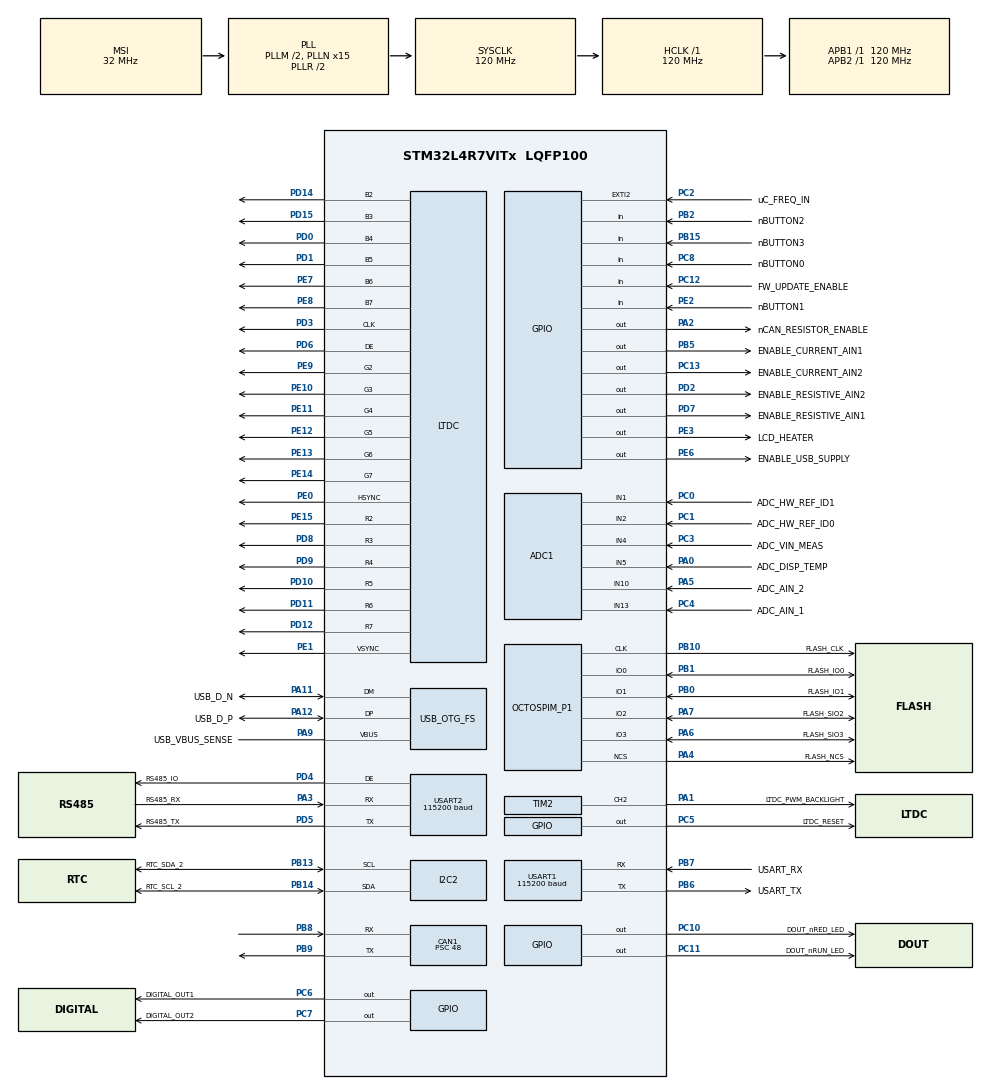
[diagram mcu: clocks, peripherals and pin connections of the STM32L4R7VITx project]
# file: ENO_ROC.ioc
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ADC1.Channel-0\#ChannelRegularConversion=ADC_CHANNEL_2
ADC1.Channel-1\#ChannelRegularConversion=ADC_CHANNEL_1
ADC1.Channel-2\#ChannelRegularConversion=ADC_CHANNEL_4
ADC1.Channel-3\#ChannelRegularConversion=ADC_CHANNEL_5
ADC1.Channel-4\#ChannelRegularConversion=ADC_CHANNEL_13
ADC1.Channel-5\#ChannelRegularConversion=ADC_CHANNEL_10
ADC1.Channel-6\#ChannelRegularConversion=ADC_CHANNEL_TEMPSENSOR
ADC1.Channel-7\#ChannelRegularConversion=ADC_CHANNEL_VREFINT
ADC1.ClockPrescaler=ADC_CLOCK_ASYNC_DIV12
ADC1.ContinuousConvMode=ENABLE
ADC1.DMAContinuousRequests=ENABLE
ADC1.EOCSelection=ADC_EOC_SEQ_CONV
ADC1.ExternalTrigConv=ADC_SOFTWARE_START
ADC1.NbrOfConversion=8
ADC1.NbrOfConversionFlag=1
ADC1.OffsetNumber-0\#ChannelRegularConversion=ADC_OFFSET_NONE
ADC1.OffsetNumber-1\#ChannelRegularConversion=ADC_OFFSET_NONE
ADC1.OffsetNumber-2\#ChannelRegularConversion=ADC_OFFSET_NONE
ADC1.OffsetNumber-3\#ChannelRegularConversion=ADC_OFFSET_NONE
ADC1.OffsetNumber-4\#ChannelRegularConversion=ADC_OFFSET_NONE
ADC1.OffsetNumber-5\#ChannelRegularConversion=ADC_OFFSET_NONE
ADC1.OffsetNumber-6\#ChannelRegularConversion=ADC_OFFSET_NONE
ADC1.OffsetNumber-7\#ChannelRegularConversion=ADC_OFFSET_NONE
ADC1.Overrun=ADC_OVR_DATA_OVERWRITTEN
ADC1.Rank-0\#ChannelRegularConversion=1
ADC1.Rank-1\#ChannelRegularConversion=2
ADC1.Rank-2\#ChannelRegularConversion=3
ADC1.Rank-3\#ChannelRegularConversion=4
ADC1.Rank-4\#ChannelRegularConversion=5
ADC1.Rank-5\#ChannelRegularConversion=6
ADC1.Rank-6\#ChannelRegularConversion=7
ADC1.Rank-7\#ChannelRegularConversion=8
ADC1.SamplingTime-0\#ChannelRegularConversion=ADC_SAMPLETIME_247CYCLES_5
ADC1.SamplingTime-1\#ChannelRegularConversion=ADC_SAMPLETIME_247CYCLES_5
ADC1.SamplingTime-2\#ChannelRegularConversion=ADC_SAMPLETIME_247CYCLES_5
ADC1.SamplingTime-3\#ChannelRegularConversion=ADC_SAMPLETIME_247CYCLES_5
ADC1.SamplingTime-4\#ChannelRegularConversion=ADC_SAMPLETIME_247CYCLES_5
ADC1.SamplingTime-5\#ChannelRegularConversion=ADC_SAMPLETIME_247CYCLES_5
ADC1.SamplingTime-6\#ChannelRegularConversion=ADC_SAMPLETIME_247CYCLES_5
ADC1.SamplingTime-7\#ChannelRegularConversion=ADC_SAMPLETIME_640CYCLES_5
ADC1.master=1
CAN1.BS1=CAN_BS1_4TQ
CAN1.BS2=CAN_BS2_5TQ
CAN1.CalculateBaudRate=250000
CAN1.CalculateTimeBit=4000
CAN1.CalculateTimeQuantum=400.0
CAN1.Mode=CAN_MODE_NORMAL
CAN1.NART=ENABLE
CAN1.Prescaler=48
CAN1.SJW=CAN_SJW_1TQ
DMA2D.ColorMode=DMA2D_OUTPUT_RGB888
DMA2D.InputAlphaForeground=255
DMA2D.InputColorModeForeground=DMA2D_INPUT_RGB888
DMA2D.Mode=DMA2D_M2M
Dma.ADC1.0.Direction=DMA_PERIPH_TO_MEMORY
Dma.ADC1.0.EventEnable=DISABLE
Dma.ADC1.0.Instance=DMA1_Channel1
Dma.ADC1.0.MemDataAlignment=DMA_MDATAALIGN_HALFWORD
Dma.ADC1.0.MemInc=DMA_MINC_ENABLE
Dma.ADC1.0.Mode=DMA_CIRCULAR
Dma.ADC1.0.PeriphDataAlignment=DMA_PDATAALIGN_HALFWORD
Dma.ADC1.0.PeriphInc=DMA_PINC_DISABLE
Dma.ADC1.0.Polarity=HAL_DMAMUX_REQUEST_GEN_RISING
Dma.ADC1.0.Priority=DMA_PRIORITY_LOW
Dma.ADC1.0.RequestNumber=1
Dma.ADC1.0.SignalID=NONE
Dma.ADC1.0.SyncEnable=DISABLE
Dma.ADC1.0.SyncPolarity=HAL_DMAMUX_SYNC_NO_EVENT
Dma.ADC1.0.SyncRequestNumber=1
Dma.ADC1.0.SyncSignalID=NONE
Dma.Request0=ADC1
Dma.Request1=USART1_RX
Dma.Request2=USART2_RX
Dma.USART1_RX.1.Direction=DMA_PERIPH_TO_MEMORY
Dma.USART1_RX.1.EventEnable=DISABLE
Dma.USART1_RX.1.Instance=DMA1_Channel2
Dma.USART1_RX.1.MemDataAlignment=DMA_MDATAALIGN_BYTE
Dma.USART1_RX.1.MemInc=DMA_MINC_ENABLE
Dma.USART1_RX.1.Mode=DMA_CIRCULAR
Dma.USART1_RX.1.PeriphDataAlignment=DMA_PDATAALIGN_BYTE
Dma.USART1_RX.1.PeriphInc=DMA_PINC_DISABLE
Dma.USART1_RX.1.Polarity=HAL_DMAMUX_REQUEST_GEN_RISING
Dma.USART1_RX.1.Priority=DMA_PRIORITY_LOW
Dma.USART1_RX.1.RequestNumber=1
Dma.USART1_RX.1.SignalID=NONE
Dma.USART1_RX.1.SyncEnable=DISABLE
Dma.USART1_RX.1.SyncPolarity=HAL_DMAMUX_SYNC_NO_EVENT
Dma.USART1_RX.1.SyncRequestNumber=1
Dma.USART1_RX.1.SyncSignalID=NONE
Dma.USART2_RX.2.Direction=DMA_PERIPH_TO_MEMORY
Dma.USART2_RX.2.EventEnable=DISABLE
Dma.USART2_RX.2.Instance=DMA1_Channel3
Dma.USART2_RX.2.MemDataAlignment=DMA_MDATAALIGN_BYTE
Dma.USART2_RX.2.MemInc=DMA_MINC_ENABLE
Dma.USART2_RX.2.Mode=DMA_CIRCULAR
Dma.USART2_RX.2.PeriphDataAlignment=DMA_PDATAALIGN_BYTE
Dma.USART2_RX.2.PeriphInc=DMA_PINC_DISABLE
Dma.USART2_RX.2.Polarity=HAL_DMAMUX_REQUEST_GEN_RISING
Dma.USART2_RX.2.Priority=DMA_PRIORITY_LOW
Dma.USART2_RX.2.RequestNumber=1
Dma.USART2_RX.2.SignalID=NONE
Dma.USART2_RX.2.SyncEnable=DISABLE
Dma.USART2_RX.2.SyncPolarity=HAL_DMAMUX_SYNC_NO_EVENT
Dma.USART2_RX.2.SyncRequestNumber=1
Dma.USART2_RX.2.SyncSignalID=NONE
FATFS._FS_EXFAT=0
FATFS._FS_LOCK=0
FATFS._FS_REENTRANT=0
FATFS._FS_TIMEOUT=100000
FATFS._FS_TINY=1
FATFS._LFN_UNICODE=0
FATFS._MAX_LFN=64
FATFS._MAX_SS=4096
FATFS._MIN_SS=4096
FATFS._USE_FIND=1
FATFS._USE_LFN=1
FATFS._USE_MUTEX=0
FATFS._USE_TRIM=0
FREERTOS.Tasks01=defaultTask,24,1024,StartDefaultTask,Default,NULL,Dynamic,NULL,NULL;TouchGfx_Task,8,2048,StartTouchGfx,Default,NULL,Dynamic,NULL,NULL
FREERTOS.configCHECK_FOR_STACK_OVERFLOW=0
FREERTOS.configENABLE_FPU=1
FREERTOS.configTOTAL_HEAP_SIZE=16384
FREERTOS.configUSE_NEWLIB_REENTRANT=1
FREERTOS.copyHeapFile=1
I2C2.Timing=0x30A175AB
LTDC.ActiveH=240
LTDC.ActiveW=320
LTDC.Alpha0_L0=255
LTDC.Alpha_L0=255
LTDC.Blue=255
LTDC.Blue_L0=255
LTDC.Green=255
LTDC.Green_L0=255
LTDC.HBP=68
LTDC.HFP=4
LTDC.HSync=1
LTDC.ImageHeight_L0=240
LTDC.ImageWidth_L0=320
LTDC.Layers=0
LTDC.PCPolarity=LTDC_PCPOLARITY_IIPC
LTDC.PixelFormat_L0=LTDC_PIXEL_FORMAT_RGB888
LTDC.Red=255
LTDC.Red_L0=255
LTDC.VBP=18
LTDC.VFP=4
LTDC.VSync=1
LTDC.WindowX1_L0=320
LTDC.WindowY1_L0=240
Mcu.Family=STM32L4
Mcu.Name=STM32L4R7VITx
Mcu.Package=LQFP100
NVIC.ADC1_IRQn=true\:10\:0\:true\:false\:true\:true\:true\:true\:true
NVIC.CAN1_RX0_IRQn=true\:5\:0\:false\:false\:true\:true\:true\:true\:true
NVIC.DMA1_Channel1_IRQn=true\:5\:0\:false\:false\:true\:false\:false\:true\:true
NVIC.DMA1_Channel2_IRQn=true\:5\:0\:false\:false\:true\:true\:false\:true\:true
NVIC.DMA1_Channel3_IRQn=true\:5\:0\:false\:false\:true\:true\:false\:true\:true
NVIC.DMA2D_IRQn=true\:5\:0\:false\:false\:true\:true\:true\:true\:true
NVIC.EXTI2_IRQn=true\:5\:0\:false\:false\:true\:true\:true\:false\:true
NVIC.LTDC_IRQn=true\:5\:0\:false\:false\:true\:true\:true\:true\:true
NVIC.OTG_FS_IRQn=true\:5\:0\:false\:false\:true\:true\:false\:true\:true
NVIC.PriorityGroup=NVIC_PRIORITYGROUP_4
NVIC.TIM1_UP_TIM16_IRQn=true\:5\:0\:false\:false\:true\:false\:false\:true\:true
NVIC.TIM6_DAC_IRQn=true\:5\:0\:false\:false\:true\:true\:true\:true\:true
NVIC.TIM7_IRQn=true\:10\:0\:true\:false\:true\:true\:true\:true\:true
NVIC.TimeBase=TIM1_UP_TIM16_IRQn
NVIC.TimeBaseIP=TIM1
NVIC.USART1_IRQn=true\:5\:0\:false\:false\:true\:true\:true\:true\:true
NVIC.USART2_IRQn=true\:5\:0\:false\:false\:true\:true\:true\:true\:true
OCTOSPI1.ClockMode=HAL_OSPI_CLOCK_MODE_0
OCTOSPI1.ClockPrescaler=1
OCTOSPI1.DelayBlockBypass=HAL_OSPI_DELAY_BLOCK_BYPASSED
OCTOSPI1.DeviceSize=22
OCTOSPI1.FifoThreshold=1
OCTOSPI1.MemoryType=HAL_OSPI_MEMTYPE_MACRONIX
PA0.GPIO_Label=ADC_DISP_TEMP
PA0.Signal=ADCx_IN5
PA1.GPIO_Label=LTDC_PWM_BACKLIGHT
PA1.Signal=S_TIM2_CH2
PA10.GPIO_Label=USB_OTG_ID
PA10.Signal=USB_OTG_FS_ID
PA11.GPIO_Label=USB_D_N
PA11.Mode=Device_Only
PA11.Signal=USB_OTG_FS_DM
PA12.GPIO_Label=USB_D_P
PA12.Mode=Device_Only
PA12.Signal=USB_OTG_FS_DP
PA13\ (JTMS/SWDIO).GPIO_Label=JTMS/SWDIO
PA13\ (JTMS/SWDIO).Mode=JTAG_5_pins
PA13\ (JTMS/SWDIO).Signal=SYS_JTMS-SWDIO
PA14\ (JTCK/SWCLK).GPIO_Label=JTCK/SWCLK
PA14\ (JTCK/SWCLK).Mode=JTAG_5_pins
PA14\ (JTCK/SWCLK).Signal=SYS_JTCK-SWCLK
PA15\ (JTDI).Mode=JTAG_5_pins
PA15\ (JTDI).Signal=SYS_JTDI
PA2.GPIO_Label=nCAN_RESISTOR_ENABLE
PA2.PinState=GPIO_PIN_SET
PA2.Signal=GPIO_Output
PA3.GPIO_Label=RS485_RX
PA3.Mode=Asynchronous
PA3.Signal=USART2_RX
PA4.GPIO_Label=FLASH_NCS
PA4.Mode=OCTOSPI1_Port1_NCS
PA4.Signal=OCTOSPIM_P1_NCS
PA5.GPIO_Label=ADC_AIN_2
PA5.Signal=ADCx_IN10
PA6.GPIO_Label=FLASH_SIO3
PA6.Mode=OCTOSPI1_IOL_Port1L
PA6.Signal=OCTOSPIM_P1_IO3
PA7.GPIO_Label=FLASH_SIO2
PA7.Mode=OCTOSPI1_IOL_Port1L
PA7.Signal=OCTOSPIM_P1_IO2
PA9.GPIO_Label=USB_VBUS_SENSE
PA9.Mode=Activate_VBUS
PA9.Signal=USB_OTG_FS_VBUS
PB0.GPIO_Label=FLASH_IO1
PB0.Mode=OCTOSPI1_IOL_Port1L
PB0.Signal=OCTOSPIM_P1_IO1
PB1.GPIO_Label=FLASH_IO0
PB1.Mode=OCTOSPI1_IOL_Port1L
PB1.Signal=OCTOSPIM_P1_IO0
PB10.GPIO_Label=FLASH_CLK
PB10.Mode=O1_P1_CLK
PB10.Signal=OCTOSPIM_P1_CLK
PB13.GPIO_Label=RTC_SDA_2
PB13.Mode=I2C
PB13.Signal=I2C2_SCL
PB14.GPIO_Label=RTC_SCL_2
PB14.Mode=I2C
PB14.Signal=I2C2_SDA
PB15.GPIO_Label=nBUTTON3
PB15.Signal=GPIO_Input
PB2.GPIO_Label=nBUTTON2
PB2.Signal=GPIO_Input
PB3\ (JTDO/TRACESWO).GPIO_Label=JTDO/TRACESWO
PB3\ (JTDO/TRACESWO).Mode=JTAG_5_pins
PB3\ (JTDO/TRACESWO).Signal=SYS_JTDO-SWO
PB4\ (NJTRST).GPIO_Label=NJTRST
PB4\ (NJTRST).Mode=JTAG_5_pins
PB4\ (NJTRST).Signal=SYS_JTRST
PB5.GPIO_Label=ENABLE_CURRENT_AIN1
PB5.Signal=GPIO_Output
PB6.GPIO_Label=USART_TX
PB6.Mode=Asynchronous
PB6.Signal=USART1_TX
PB7.GPIO_Label=USART_RX
PB7.Mode=Asynchronous
PB7.Signal=USART1_RX
PB8.GPIO_FM8=__NULL
PB8.GPIO_PuPd=GPIO_PULLUP
PB8.Mode=CAN_Activate
PB8.Signal=CAN1_RX
PB9.GPIO_FM9=__NULL
PB9.Mode=CAN_Activate
PB9.Signal=CAN1_TX
PC0.GPIO_Label=ADC_HW_REF_ID1
PC0.Signal=ADCx_IN1
PC1.GPIO_Label=ADC_HW_REF_ID0
PC1.Signal=ADCx_IN2
PC10.GPIO_Label=DOUT_nRED_LED
PC10.Signal=GPIO_Output
PC11.GPIO_Label=DOUT_nRUN_LED
PC11.Signal=GPIO_Output
PC12.GPIO_Label=FW_UPDATE_ENABLE
PC12.Signal=GPIO_Input
PC13.GPIO_Label=ENABLE_CURRENT_AIN2
PC13.Signal=GPIO_Output
PC14-OSC32_IN\ (PC14).Mode=LSE-External-Oscillator
PC14-OSC32_IN\ (PC14).Signal=RCC_OSC32_IN
PC15-OSC32_OUT\ (PC15).Mode=LSE-External-Oscillator
PC15-OSC32_OUT\ (PC15).Signal=RCC_OSC32_OUT
PC2.GPIO_Label=uC_FREQ_IN
PC2.GPIO_ModeDefaultEXTI=GPIO_MODE_IT_FALLING
PC2.Signal=GPXTI2
PC3.GPIO_Label=ADC_VIN_MEAS
PC3.Signal=ADCx_IN4
PC4.GPIO_Label=ADC_AIN_1
PC4.Signal=ADCx_IN13
PC5.GPIO_Label=LTDC_RESET
PC5.PinState=GPIO_PIN_SET
PC5.Signal=GPIO_Output
PC6.GPIO_Label=DIGITAL_OUT1
PC6.Signal=GPIO_Output
PC7.GPIO_Label=DIGITAL_OUT2
PC7.Signal=GPIO_Output
PC8.GPIO_Label=nBUTTON0
PC8.Signal=GPIO_Input
PD0.Mode=RGB666
PD0.Signal=LTDC_B4
PD1.Mode=RGB666
PD1.Signal=LTDC_B5
PD10.Mode=RGB666
PD10.Signal=LTDC_R5
PD11.Mode=RGB666
PD11.Signal=LTDC_R6
PD12.Mode=RGB666
PD12.Signal=LTDC_R7
PD14.Mode=RGB666
PD14.Signal=LTDC_B2
PD15.Mode=RGB666
PD15.Signal=LTDC_B3
PD2.GPIO_Label=ENABLE_RESISTIVE_AIN2
PD2.Signal=GPIO_Output
PD3.Mode=RGB666
PD3.Signal=LTDC_CLK
PD4.GPIO_Label=RS485_IO
PD4.Mode=Hardware Flow Control (RS485)
PD4.Signal=USART2_DE
PD5.GPIO_Label=RS485_TX
PD5.Mode=Asynchronous
PD5.Signal=USART2_TX
PD6.Mode=RGB666
PD6.Signal=LTDC_DE
PD7.GPIO_Label=ENABLE_RESISTIVE_AIN1
PD7.Signal=GPIO_Output
PD8.Mode=RGB666
PD8.Signal=LTDC_R3
PD9.Mode=RGB666
PD9.Signal=LTDC_R4
PE0.Mode=RGB666
PE0.Signal=LTDC_HSYNC
PE1.Mode=RGB666
PE1.Signal=LTDC_VSYNC
PE10.Mode=RGB666
PE10.Signal=LTDC_G3
PE11.Mode=RGB666
PE11.Signal=LTDC_G4
PE12.Mode=RGB666
PE12.Signal=LTDC_G5
PE13.Mode=RGB666
PE13.Signal=LTDC_G6
PE14.Mode=RGB666
PE14.Signal=LTDC_G7
PE15.Mode=RGB666
PE15.Signal=LTDC_R2
PE2.GPIO_Label=nBUTTON1
PE2.Signal=GPIO_Input
PE3.GPIO_Label=LCD_HEATER
PE3.Signal=GPIO_Output
PE6.GPIO_Label=ENABLE_USB_SUPPLY
PE6.Signal=GPIO_Output
PE7.Mode=RGB666
PE7.Signal=LTDC_B6
PE8.Mode=RGB666
PE8.Signal=LTDC_B7
PE9.Mode=RGB666
PE9.Signal=LTDC_G2
PH0-OSC_IN\ (PH0).Mode=HSE-External-Oscillator
PH0-OSC_IN\ (PH0).Signal=RCC_OSC_IN
PH1-OSC_OUT\ (PH1).Mode=HSE-External-Oscillator
PH1-OSC_OUT\ (PH1).Signal=RCC_OSC_OUT
ProjectManager.HeapSize=0x1000
ProjectManager.StackSize=0x1000
ProjectManager.TargetToolchain=STM32CubeIDE
RCC.ADCFreq_Value=48000000
RCC.AHBFreq_Value=120000000
RCC.APB1Freq_Value=120000000
RCC.APB1TimFreq_Value=120000000
RCC.APB2Freq_Value=120000000
RCC.APB2TimFreq_Value=120000000
RCC.CortexFreq_Value=120000000
RCC.HCLKFreq_Value=120000000
RCC.HSE_VALUE=25000000
RCC.HSI48_VALUE=48000000
RCC.HSI_VALUE=16000000
RCC.MSICalibrationValue=64
RCC.MSIClockRange=RCC_MSIRANGE_10
RCC.MSI_VALUE=32000000
RCC.OCTOSPIMCLockSelection=RCC_OSPICLKSOURCE_PLL
RCC.PLLM1=2
RCC.PLLM2=3
RCC.PLLM3=4
RCC.PLLN=15
RCC.PLLSAI1N=27
RCC.PLLSAI1Q=RCC_PLLQ_DIV6
RCC.PLLSAI1R=RCC_PLLR_DIV6
RCC.PLLSAI2N=13
RCC.PLLSAI2R=RCC_PLLR_DIV8
RCC.SYSCLKFreq_VALUE=120000000
RCC.SYSCLKSource=RCC_SYSCLKSOURCE_PLLCLK
RCC.USBFreq_Value=48000000
RCC.VCOOutputFreq_Value=240000000
SH.ADCx_IN1.0=ADC1_IN1,IN1-Single-Ended
SH.ADCx_IN10.0=ADC1_IN10,IN10-Single-Ended
SH.ADCx_IN13.0=ADC1_IN13,IN13-Single-Ended
SH.ADCx_IN2.0=ADC1_IN2,IN2-Single-Ended
SH.ADCx_IN4.0=ADC1_IN4,IN4-Single-Ended
SH.ADCx_IN5.0=ADC1_IN5,IN5-Single-Ended
SH.S_TIM2_CH2.0=TIM2_CH2,PWM Generation2 CH2
STMicroelectronics.X-CUBE-TOUCHGFX.4.25.0.ApplicationCcGraphicsJjApplication=TouchGFXOoGenerator
STMicroelectronics.X-CUBE-TOUCHGFX.4.25.0.tgfx_buffering_strategy=Double
STMicroelectronics.X-CUBE-TOUCHGFX.4.25.0.tgfx_custom_height=240
STMicroelectronics.X-CUBE-TOUCHGFX.4.25.0.tgfx_display_interface=disp_ltdc
STMicroelectronics.X-CUBE-TOUCHGFX.4.25.0.tgfx_hardware_accelerator=dma_2d
STMicroelectronics.X-CUBE-TOUCHGFX.4.25.0.tgfx_nema_cl_size=8192
STMicroelectronics.X-CUBE-TOUCHGFX.4.25.0.tgfx_vsync=vsync_ltdc
STMicroelectronics.X-CUBE-TOUCHGFX.4.25.0_IsPackSelfContextualization=true
TIM2.AutoReloadPreload=TIM_AUTORELOAD_PRELOAD_ENABLE
TIM2.Channel-PWM\ Generation2\ CH2=TIM_CHANNEL_2
TIM2.OCFastMode_PWM-PWM\ Generation2\ CH2=TIM_OCFAST_ENABLE
TIM2.Period=16383
TIM2.Prescaler=0
TIM6.AutoReloadPreload=TIM_AUTORELOAD_PRELOAD_DISABLE
TIM6.Period=65535
TIM6.Prescaler=60
TIM6.TIM_MasterOutputTrigger=TIM_TRGO_RESET
TIM7.AutoReloadPreload=TIM_AUTORELOAD_PRELOAD_ENABLE
TIM7.Period=1000
TIM7.Prescaler=119
USART1.BaudRate=115200
USART1.FIFOMode=FIFOMODE_DISABLE
USART1.VirtualMode-Asynchronous=VM_ASYNC
USART2.BaudRate=115200
USART2.SwapParam=ADVFEATURE_SWAP_DISABLE
USART2.VirtualMode-Asynchronous=VM_ASYNC
USART2.VirtualMode-Hardware\ Flow\ Control\ (RS485)=VM_ASYNC
USB_DEVICE.CLASS_NAME_FS=MSC
USB_DEVICE.MANUFACTURER_STRING=Enovation Controls LLC
USB_DEVICE.MSC_MEDIA_PACKET=4096
USB_DEVICE.PRODUCT_STRING_MSC_FS=ENO Mass Storage
USB_DEVICE.VID=0x2B28
USB_DEVICE.VirtualMode=Msc
USB_DEVICE.VirtualModeFS=Msc_FS
USB_OTG_FS.VirtualMode=Device_Only
VP_ADC1_TempSens_Input.Mode=IN-TempSens
VP_ADC1_Vref_Input.Mode=IN-Vrefint
VP_CRC_VS_CRC.Mode=CRC_Activate
VP_DMA2D_VS_DMA2D.Mode=DMA2D_Activate
VP_FATFS_VS_Generic.Mode=User_defined
VP_FREERTOS_VS_CMSIS_V2.Mode=CMSIS_V2
VP_OCTOSPI1_VS_quad.Mode=quad_mode
VP_RNG_VS_RNG.Mode=RNG_Activate
VP_STMicroelectronics.X-CUBE-TOUCHGFX_VS_GraphicsJjApplication_4.25.0.Mode=GraphicsJjApplication
VP_SYS_VS_tim1.Mode=TIM1
VP_TIM2_VS_ClockSourceINT.Mode=Internal
VP_TIM6_VS_ClockSourceINT.Mode=Enable_Timer
VP_TIM7_VS_ClockSourceINT.Mode=Enable_Timer
VP_USB_DEVICE_VS_USB_DEVICE_MSC_FS.Mode=MSC_FS
board=custom

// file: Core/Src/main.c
/* USER CODE BEGIN Header */
/**
  ******************************************************************************
  * @file           : main.c
  * @brief          : Main program body
  ******************************************************************************
  * @attention
  *
  * Copyright (c) 2024 STMicroelectronics.
  * All rights reserved.
  *
  * This software is licensed under terms that can be found in the LICENSE file
  * in the root directory of this software component.
  * If no LICENSE file comes with this software, it is provided AS-IS.
  *
  ******************************************************************************
  */
/* USER CODE END Header */
#include "main.h"
#include "cmsis_os.h"
#include "fatfs.h"
#include "app_touchgfx.h"
#include "usb_device.h"

/* USER CODE BEGIN Includes */
#include "version.h"
#include "MX25L3233F/mx25l3233f.h"
#include "fs_layer.h"
#include "adc_helper.h"

//EC code
#include <ConfigMemory.h>
#include <TickTimers.h>
#include <CAN.h>
#include <Digital_outputs.h>
#include <MiscFunctions.h>
#include <nonVolStorage.h>
#include <Frequency.h>
#include <analogs.h>
#include "LCD_heater.h"

#include "SystemHealthManager.h"
#include "pdm.h"
#include "Engine_App.h"
#include "IO_Mapping.h"

/* USER CODE END Includes */

/* USER CODE BEGIN PD */

//Firmware version (displayed on splash screen)

//                        "123456789012345678901234"
char firmware_version[] = "Base project V2.00.00 ";

/* USER CODE END PD */

ADC_HandleTypeDef hadc1;
DMA_HandleTypeDef hdma_adc1;

CAN_HandleTypeDef hcan1;

CRC_HandleTypeDef hcrc;

DMA2D_HandleTypeDef hdma2d;

I2C_HandleTypeDef hi2c2;

LTDC_HandleTypeDef hltdc;

OSPI_HandleTypeDef hospi1;

RNG_HandleTypeDef hrng;

TIM_HandleTypeDef htim2;
TIM_HandleTypeDef htim6;
TIM_HandleTypeDef htim7;

UART_HandleTypeDef huart1;
UART_HandleTypeDef huart2;
DMA_HandleTypeDef hdma_usart1_rx;
DMA_HandleTypeDef hdma_usart2_rx;

/* Definitions for defaultTask */
osThreadId_t defaultTaskHandle;
const osThreadAttr_t defaultTask_attributes = {
  .name = "defaultTask",
  .stack_size = 1024 * 4,
  .priority = (osPriority_t) osPriorityNormal,
};
/* Definitions for TouchGfx_Task */
osThreadId_t TouchGfx_TaskHandle;
const osThreadAttr_t TouchGfx_Task_attributes = {
  .name = "TouchGfx_Task",
  .stack_size = 2048 * 4,
  .priority = (osPriority_t) osPriorityLow,
};
/* USER CODE BEGIN PV */
#define USE_PRINTF // enables printf output on selected UART

#define USE_DEBUG_UART

#ifdef USE_DEBUG_UART
UART_HandleTypeDef* phuart = &huart1;
#else
  UART_HandleTypeDef* phuart = &huart2;
#endif

/* USER CODE END PV */

void SystemClock_Config(void);
void PeriphCommonClock_Config(void);
static void MX_GPIO_Init(void);
static void MX_DMA_Init(void);
static void MX_LTDC_Init(void);
static void MX_OCTOSPI1_Init(void);
static void MX_CRC_Init(void);
static void MX_DMA2D_Init(void);
static void MX_ADC1_Init(void);
static void MX_TIM2_Init(void);
static void MX_USART2_UART_Init(void);
static void MX_CAN1_Init(void);
static void MX_USART1_UART_Init(void);
static void MX_I2C2_Init(void);
static void MX_RNG_Init(void);
static void MX_TIM7_Init(void);
static void MX_TIM6_Init(void);
void StartDefaultTask(void *argument);
void StartTouchGfx(void *argument);

int main(void)
{

  /* MCU Configuration--------------------------------------------------------*/

  /* Reset of all peripherals, Initializes the Flash interface and the Systick. */
  HAL_Init();

  /* Configure the system clock */
  SystemClock_Config();

  /* Configure the peripherals common clocks */
  PeriphCommonClock_Config();

  /* Initialize all configured peripherals */
  MX_GPIO_Init();
  MX_DMA_Init();
  MX_LTDC_Init();
  MX_OCTOSPI1_Init();
  MX_CRC_Init();
  MX_DMA2D_Init();
  MX_ADC1_Init();
  MX_TIM2_Init();
  MX_USART2_UART_Init();
  MX_CAN1_Init();
  MX_USART1_UART_Init();
  MX_I2C2_Init();
  MX_RNG_Init();
  MX_TIM7_Init();
  MX_FATFS_Init();
  MX_TIM6_Init();
  MX_TouchGFX_Init();
  /* Call PreOsInit function */
  MX_TouchGFX_PreOSInit();
  /* USER CODE BEGIN 2 */

  printf("BSP version %d.%d.%d\n", BSP_VERSION_MAJOR, BSP_VERSION_MINOR, BSP_VERSION_PATCH);
  CAN_InitTask();

  SystemHealth_Init();
  /* Initialize flash driver */
  FlashDrv_ConfigDef  config = {.maxSPIFrequencyInkHz = 120000, .nrIOLines = 4};
  MX25L32_Init(config);

  FS_Init(); // Init littlefs here or in a FreeRtos task
  FATFS_Init();

  ADC_startSampling();

  /* USER CODE END 2 */

  /* Init scheduler */
  osKernelInitialize();

  /* Create the thread(s) */
  /* creation of defaultTask */
  defaultTaskHandle = osThreadNew(StartDefaultTask, NULL, &defaultTask_attributes);

  /* creation of TouchGfx_Task */
  TouchGfx_TaskHandle = osThreadNew(StartTouchGfx, NULL, &TouchGfx_Task_attributes);

  /* USER CODE BEGIN RTOS_THREADS */
  /* add threads, ... */
  ADC_InitTask();

  /* USER CODE END RTOS_THREADS */

  /* Start scheduler */
  osKernelStart();

  /* We should never get here as control is now taken by the scheduler */

  /* Infinite loop */
  while (1)
  {

  }
}

void SystemClock_Config(void)
{
  RCC_OscInitTypeDef RCC_OscInitStruct = {0};
  RCC_ClkInitTypeDef RCC_ClkInitStruct = {0};

  /** Configure the main internal regulator output voltage
  */
  if (HAL_PWREx_ControlVoltageScaling(PWR_REGULATOR_VOLTAGE_SCALE1_BOOST) != HAL_OK)
  {
    Error_Handler();
  }

  /** Configure LSE Drive Capability
  */
  HAL_PWR_EnableBkUpAccess();
  __HAL_RCC_LSEDRIVE_CONFIG(RCC_LSEDRIVE_LOW);

  /** Initializes the RCC Oscillators according to the specified parameters
  * in the RCC_OscInitTypeDef structure.
  */
  RCC_OscInitStruct.OscillatorType = RCC_OSCILLATORTYPE_LSE|RCC_OSCILLATORTYPE_MSI;
  RCC_OscInitStruct.LSEState = RCC_LSE_ON;
  RCC_OscInitStruct.MSIState = RCC_MSI_ON;
  RCC_OscInitStruct.MSICalibrationValue = 64;
  RCC_OscInitStruct.MSIClockRange = RCC_MSIRANGE_10;
  RCC_OscInitStruct.PLL.PLLState = RCC_PLL_ON;
  RCC_OscInitStruct.PLL.PLLSource = RCC_PLLSOURCE_MSI;
  RCC_OscInitStruct.PLL.PLLM = 2;
  RCC_OscInitStruct.PLL.PLLN = 15;
  RCC_OscInitStruct.PLL.PLLP = RCC_PLLP_DIV2;
  RCC_OscInitStruct.PLL.PLLQ = RCC_PLLQ_DIV2;
  RCC_OscInitStruct.PLL.PLLR = RCC_PLLR_DIV2;
  if (HAL_RCC_OscConfig(&RCC_OscInitStruct) != HAL_OK)
  {
    Error_Handler();
  }

  /** Initializes the CPU, AHB and APB buses clocks
  */
  RCC_ClkInitStruct.ClockType = RCC_CLOCKTYPE_HCLK|RCC_CLOCKTYPE_SYSCLK
                              |RCC_CLOCKTYPE_PCLK1|RCC_CLOCKTYPE_PCLK2;
  RCC_ClkInitStruct.SYSCLKSource = RCC_SYSCLKSOURCE_PLLCLK;
  RCC_ClkInitStruct.AHBCLKDivider = RCC_SYSCLK_DIV1;
  RCC_ClkInitStruct.APB1CLKDivider = RCC_HCLK_DIV1;
  RCC_ClkInitStruct.APB2CLKDivider = RCC_HCLK_DIV1;

  if (HAL_RCC_ClockConfig(&RCC_ClkInitStruct, FLASH_LATENCY_5) != HAL_OK)
  {
    Error_Handler();
  }

  /** Enable MSI Auto calibration
  */
  HAL_RCCEx_EnableMSIPLLMode();
}

void PeriphCommonClock_Config(void)
{
  RCC_PeriphCLKInitTypeDef PeriphClkInit = {0};

  /** Initializes the peripherals clock
  */
  PeriphClkInit.PeriphClockSelection = RCC_PERIPHCLK_USB|RCC_PERIPHCLK_RNG
                              |RCC_PERIPHCLK_ADC;
  PeriphClkInit.AdcClockSelection = RCC_ADCCLKSOURCE_PLLSAI1;
  PeriphClkInit.UsbClockSelection = RCC_USBCLKSOURCE_PLLSAI1;
  PeriphClkInit.RngClockSelection = RCC_RNGCLKSOURCE_PLLSAI1;
  PeriphClkInit.PLLSAI1.PLLSAI1Source = RCC_PLLSOURCE_MSI;
  PeriphClkInit.PLLSAI1.PLLSAI1M = 3;
  PeriphClkInit.PLLSAI1.PLLSAI1N = 27;
  PeriphClkInit.PLLSAI1.PLLSAI1P = RCC_PLLP_DIV2;
  PeriphClkInit.PLLSAI1.PLLSAI1Q = RCC_PLLQ_DIV6;
  PeriphClkInit.PLLSAI1.PLLSAI1R = RCC_PLLR_DIV6;
  PeriphClkInit.PLLSAI1.PLLSAI1ClockOut = RCC_PLLSAI1_48M2CLK|RCC_PLLSAI1_ADC1CLK;
  if (HAL_RCCEx_PeriphCLKConfig(&PeriphClkInit) != HAL_OK)
  {
    Error_Handler();
  }
}

static void MX_ADC1_Init(void)
{

  ADC_ChannelConfTypeDef sConfig = {0};

  /** Common config
  */
  hadc1.Instance = ADC1;
  hadc1.Init.ClockPrescaler = ADC_CLOCK_ASYNC_DIV12;
  hadc1.Init.Resolution = ADC_RESOLUTION_12B;
  hadc1.Init.DataAlign = ADC_DATAALIGN_RIGHT;
  hadc1.Init.ScanConvMode = ADC_SCAN_ENABLE;
  hadc1.Init.EOCSelection = ADC_EOC_SEQ_CONV;
  hadc1.Init.LowPowerAutoWait = DISABLE;
  hadc1.Init.ContinuousConvMode = ENABLE;
  hadc1.Init.NbrOfConversion = 8;
  hadc1.Init.DiscontinuousConvMode = DISABLE;
  hadc1.Init.ExternalTrigConv = ADC_SOFTWARE_START;
  hadc1.Init.ExternalTrigConvEdge = ADC_EXTERNALTRIGCONVEDGE_NONE;
  hadc1.Init.DMAContinuousRequests = ENABLE;
  hadc1.Init.Overrun = ADC_OVR_DATA_OVERWRITTEN;
  hadc1.Init.OversamplingMode = DISABLE;
  if (HAL_ADC_Init(&hadc1) != HAL_OK)
  {
    Error_Handler();
  }

  /** Configure Regular Channel
  */
  sConfig.Channel = ADC_CHANNEL_2;
  sConfig.Rank = ADC_REGULAR_RANK_1;
  sConfig.SamplingTime = ADC_SAMPLETIME_247CYCLES_5;
  sConfig.SingleDiff = ADC_SINGLE_ENDED;
  sConfig.OffsetNumber = ADC_OFFSET_NONE;
  sConfig.Offset = 0;
  if (HAL_ADC_ConfigChannel(&hadc1, &sConfig) != HAL_OK)
  {
    Error_Handler();
  }

  /** Configure Regular Channel
  */
  sConfig.Channel = ADC_CHANNEL_1;
  sConfig.Rank = ADC_REGULAR_RANK_2;
  if (HAL_ADC_ConfigChannel(&hadc1, &sConfig) != HAL_OK)
  {
    Error_Handler();
  }

  /** Configure Regular Channel
  */
  sConfig.Channel = ADC_CHANNEL_4;
  sConfig.Rank = ADC_REGULAR_RANK_3;
  if (HAL_ADC_ConfigChannel(&hadc1, &sConfig) != HAL_OK)
  {
    Error_Handler();
  }

  /** Configure Regular Channel
  */
  sConfig.Channel = ADC_CHANNEL_5;
  sConfig.Rank = ADC_REGULAR_RANK_4;
  if (HAL_ADC_ConfigChannel(&hadc1, &sConfig) != HAL_OK)
  {
    Error_Handler();
  }

  /** Configure Regular Channel
  */
  sConfig.Channel = ADC_CHANNEL_13;
  sConfig.Rank = ADC_REGULAR_RANK_5;
  if (HAL_ADC_ConfigChannel(&hadc1, &sConfig) != HAL_OK)
  {
    Error_Handler();
  }

  /** Configure Regular Channel
  */
  sConfig.Channel = ADC_CHANNEL_10;
  sConfig.Rank = ADC_REGULAR_RANK_6;
  if (HAL_ADC_ConfigChannel(&hadc1, &sConfig) != HAL_OK)
  {
    Error_Handler();
  }

  /** Configure Regular Channel
  */
  sConfig.Channel = ADC_CHANNEL_TEMPSENSOR;
  sConfig.Rank = ADC_REGULAR_RANK_7;
  if (HAL_ADC_ConfigChannel(&hadc1, &sConfig) != HAL_OK)
  {
    Error_Handler();
  }

  /** Configure Regular Channel
  */
  sConfig.Channel = ADC_CHANNEL_VREFINT;
  sConfig.Rank = ADC_REGULAR_RANK_8;
  sConfig.SamplingTime = ADC_SAMPLETIME_640CYCLES_5;
  if (HAL_ADC_ConfigChannel(&hadc1, &sConfig) != HAL_OK)
  {
    Error_Handler();
  }
  /* USER CODE BEGIN ADC1_Init 2 */
  SET_BIT(ADC1_COMMON->CCR, ADC_CCR_VREFEN);
  HAL_ADCEx_Calibration_Start(&hadc1, ADC_SINGLE_ENDED);
  /* USER CODE END ADC1_Init 2 */

}

static void MX_CAN1_Init(void)
{

  hcan1.Instance = CAN1;
  hcan1.Init.Prescaler = 48;
  hcan1.Init.Mode = CAN_MODE_NORMAL;
  hcan1.Init.SyncJumpWidth = CAN_SJW_1TQ;
  hcan1.Init.TimeSeg1 = CAN_BS1_4TQ;
  hcan1.Init.TimeSeg2 = CAN_BS2_5TQ;
  hcan1.Init.TimeTriggeredMode = DISABLE;
  hcan1.Init.AutoBusOff = DISABLE;
  hcan1.Init.AutoWakeUp = DISABLE;
  hcan1.Init.AutoRetransmission = ENABLE;
  hcan1.Init.ReceiveFifoLocked = DISABLE;
  hcan1.Init.TransmitFifoPriority = DISABLE;
  if (HAL_CAN_Init(&hcan1) != HAL_OK)
  {
    Error_Handler();
  }
  /* USER CODE BEGIN CAN1_Init 2 */
  // Enable terminal resistor
  HAL_GPIO_WritePin(nCAN_RESISTOR_ENABLE_GPIO_Port, nCAN_RESISTOR_ENABLE_Pin, GPIO_PIN_RESET);
  /* USER CODE END CAN1_Init 2 */

}

static void MX_CRC_Init(void)
{

  hcrc.Instance = CRC;
  hcrc.Init.DefaultPolynomialUse = DEFAULT_POLYNOMIAL_ENABLE;
  hcrc.Init.DefaultInitValueUse = DEFAULT_INIT_VALUE_ENABLE;
  hcrc.Init.InputDataInversionMode = CRC_INPUTDATA_INVERSION_NONE;
  hcrc.Init.OutputDataInversionMode = CRC_OUTPUTDATA_INVERSION_DISABLE;
  hcrc.InputDataFormat = CRC_INPUTDATA_FORMAT_BYTES;
  if (HAL_CRC_Init(&hcrc) != HAL_OK)
  {
    Error_Handler();
  }

}

static void MX_DMA2D_Init(void)
{

  hdma2d.Instance = DMA2D;
  hdma2d.Init.Mode = DMA2D_M2M;
  hdma2d.Init.ColorMode = DMA2D_OUTPUT_RGB888;
  hdma2d.Init.OutputOffset = 0;
  hdma2d.Init.BytesSwap = DMA2D_BYTES_REGULAR;
  hdma2d.Init.LineOffsetMode = DMA2D_LOM_PIXELS;
  hdma2d.LayerCfg[1].InputOffset = 0;
  hdma2d.LayerCfg[1].InputColorMode = DMA2D_INPUT_RGB888;
  hdma2d.LayerCfg[1].AlphaMode = DMA2D_NO_MODIF_ALPHA;
  hdma2d.LayerCfg[1].InputAlpha = 255;
  hdma2d.LayerCfg[1].AlphaInverted = DMA2D_REGULAR_ALPHA;
  hdma2d.LayerCfg[1].RedBlueSwap = DMA2D_RB_REGULAR;
  if (HAL_DMA2D_Init(&hdma2d) != HAL_OK)
  {
    Error_Handler();
  }
  if (HAL_DMA2D_ConfigLayer(&hdma2d, 1) != HAL_OK)
  {
    Error_Handler();
  }

}

static void MX_I2C2_Init(void)
{

  hi2c2.Instance = I2C2;
  hi2c2.Init.Timing = 0x30A175AB;
  hi2c2.Init.OwnAddress1 = 0;
  hi2c2.Init.AddressingMode = I2C_ADDRESSINGMODE_7BIT;
  hi2c2.Init.DualAddressMode = I2C_DUALADDRESS_DISABLE;
  hi2c2.Init.OwnAddress2 = 0;
  hi2c2.Init.OwnAddress2Masks = I2C_OA2_NOMASK;
  hi2c2.Init.GeneralCallMode = I2C_GENERALCALL_DISABLE;
  hi2c2.Init.NoStretchMode = I2C_NOSTRETCH_DISABLE;
  if (HAL_I2C_Init(&hi2c2) != HAL_OK)
  {
    Error_Handler();
  }

  /** Configure Analogue filter
  */
  if (HAL_I2CEx_ConfigAnalogFilter(&hi2c2, I2C_ANALOGFILTER_ENABLE) != HAL_OK)
  {
    Error_Handler();
  }

  /** Configure Digital filter
  */
  if (HAL_I2CEx_ConfigDigitalFilter(&hi2c2, 0) != HAL_OK)
  {
    Error_Handler();
  }

}

static void MX_LTDC_Init(void)
{

  LTDC_LayerCfgTypeDef pLayerCfg = {0};

  hltdc.Instance = LTDC;
  hltdc.Init.HSPolarity = LTDC_HSPOLARITY_AL;
  hltdc.Init.VSPolarity = LTDC_VSPOLARITY_AL;
  hltdc.Init.DEPolarity = LTDC_DEPOLARITY_AL;
  hltdc.Init.PCPolarity = LTDC_PCPOLARITY_IIPC;
  hltdc.Init.HorizontalSync = 0;
  hltdc.Init.VerticalSync = 0;
  hltdc.Init.AccumulatedHBP = 68;
  hltdc.Init.AccumulatedVBP = 18;
  hltdc.Init.AccumulatedActiveW = 388;
  hltdc.Init.AccumulatedActiveH = 258;
  hltdc.Init.TotalWidth = 392;
  hltdc.Init.TotalHeigh = 262;
  hltdc.Init.Backcolor.Blue = 255;
  hltdc.Init.Backcolor.Green = 255;
  hltdc.Init.Backcolor.Red = 255;
  if (HAL_LTDC_Init(&hltdc) != HAL_OK)
  {
    Error_Handler();
  }
  pLayerCfg.WindowX0 = 0;
  pLayerCfg.WindowX1 = 320;
  pLayerCfg.WindowY0 = 0;
  pLayerCfg.WindowY1 = 240;
  pLayerCfg.PixelFormat = LTDC_PIXEL_FORMAT_RGB888;
  pLayerCfg.Alpha = 255;
  pLayerCfg.Alpha0 = 255;
  pLayerCfg.BlendingFactor1 = LTDC_BLENDING_FACTOR1_CA;
  pLayerCfg.BlendingFactor2 = LTDC_BLENDING_FACTOR2_CA;
  pLayerCfg.FBStartAdress = 0;
  pLayerCfg.ImageWidth = 320;
  pLayerCfg.ImageHeight = 240;
  pLayerCfg.Backcolor.Blue = 255;
  pLayerCfg.Backcolor.Green = 255;
  pLayerCfg.Backcolor.Red = 255;
  if (HAL_LTDC_ConfigLayer(&hltdc, &pLayerCfg, 0) != HAL_OK)
  {
    Error_Handler();
  }

}

static void MX_OCTOSPI1_Init(void)
{

  OSPIM_CfgTypeDef OSPIM_Cfg_Struct = {0};

  /* OCTOSPI1 parameter configuration*/
  hospi1.Instance = OCTOSPI1;
  hospi1.Init.FifoThreshold = 1;
  hospi1.Init.DualQuad = HAL_OSPI_DUALQUAD_DISABLE;
  hospi1.Init.MemoryType = HAL_OSPI_MEMTYPE_MACRONIX;
  hospi1.Init.DeviceSize = 22;
  hospi1.Init.ChipSelectHighTime = 1;
  hospi1.Init.FreeRunningClock = HAL_OSPI_FREERUNCLK_DISABLE;
  hospi1.Init.ClockMode = HAL_OSPI_CLOCK_MODE_0;
  hospi1.Init.ClockPrescaler = 1;
  hospi1.Init.SampleShifting = HAL_OSPI_SAMPLE_SHIFTING_NONE;
  hospi1.Init.DelayHoldQuarterCycle = HAL_OSPI_DHQC_DISABLE;
  hospi1.Init.ChipSelectBoundary = 0;
  hospi1.Init.DelayBlockBypass = HAL_OSPI_DELAY_BLOCK_BYPASSED;
  if (HAL_OSPI_Init(&hospi1) != HAL_OK)
  {
    Error_Handler();
  }
  OSPIM_Cfg_Struct.ClkPort = 1;
  OSPIM_Cfg_Struct.NCSPort = 1;
  OSPIM_Cfg_Struct.IOLowPort = HAL_OSPIM_IOPORT_1_LOW;
  if (HAL_OSPIM_Config(&hospi1, &OSPIM_Cfg_Struct, HAL_OSPI_TIMEOUT_DEFAULT_VALUE) != HAL_OK)
  {
    Error_Handler();
  }

}

static void MX_RNG_Init(void)
{

  hrng.Instance = RNG;
  hrng.Init.ClockErrorDetection = RNG_CED_ENABLE;
  if (HAL_RNG_Init(&hrng) != HAL_OK)
  {
    Error_Handler();
  }

}

static void MX_TIM2_Init(void)
{

  TIM_ClockConfigTypeDef sClockSourceConfig = {0};
  TIM_MasterConfigTypeDef sMasterConfig = {0};
  TIM_OC_InitTypeDef sConfigOC = {0};

  htim2.Instance = TIM2;
  htim2.Init.Prescaler = 0;
  htim2.Init.CounterMode = TIM_COUNTERMODE_UP;
  htim2.Init.Period = 16383;
  htim2.Init.ClockDivision = TIM_CLOCKDIVISION_DIV1;
  htim2.Init.AutoReloadPreload = TIM_AUTORELOAD_PRELOAD_ENABLE;
  if (HAL_TIM_Base_Init(&htim2) != HAL_OK)
  {
    Error_Handler();
  }
  sClockSourceConfig.ClockSource = TIM_CLOCKSOURCE_INTERNAL;
  if (HAL_TIM_ConfigClockSource(&htim2, &sClockSourceConfig) != HAL_OK)
  {
    Error_Handler();
  }
  if (HAL_TIM_PWM_Init(&htim2) != HAL_OK)
  {
    Error_Handler();
  }
  sMasterConfig.MasterOutputTrigger = TIM_TRGO_RESET;
  sMasterConfig.MasterSlaveMode = TIM_MASTERSLAVEMODE_DISABLE;
  if (HAL_TIMEx_MasterConfigSynchronization(&htim2, &sMasterConfig) != HAL_OK)
  {
    Error_Handler();
  }
  sConfigOC.OCMode = TIM_OCMODE_PWM1;
  sConfigOC.Pulse = 0;
  sConfigOC.OCPolarity = TIM_OCPOLARITY_HIGH;
  sConfigOC.OCFastMode = TIM_OCFAST_ENABLE;
  if (HAL_TIM_PWM_ConfigChannel(&htim2, &sConfigOC, TIM_CHANNEL_2) != HAL_OK)
  {
    Error_Handler();
  }
  HAL_TIM_MspPostInit(&htim2);

}

static void MX_TIM6_Init(void)
{

  TIM_MasterConfigTypeDef sMasterConfig = {0};

  htim6.Instance = TIM6;
  htim6.Init.Prescaler = 60;
  htim6.Init.CounterMode = TIM_COUNTERMODE_UP;
  htim6.Init.Period = 65535;
  htim6.Init.AutoReloadPreload = TIM_AUTORELOAD_PRELOAD_DISABLE;
  if (HAL_TIM_Base_Init(&htim6) != HAL_OK)
  {
    Error_Handler();
  }
  sMasterConfig.MasterOutputTrigger = TIM_TRGO_RESET;
  sMasterConfig.MasterSlaveMode = TIM_MASTERSLAVEMODE_DISABLE;
  if (HAL_TIMEx_MasterConfigSynchronization(&htim6, &sMasterConfig) != HAL_OK)
  {
    Error_Handler();
  }
  /* USER CODE BEGIN TIM6_Init 2 */
  HAL_TIM_Base_Start_IT(&htim6);
  /* USER CODE END TIM6_Init 2 */

}

static void MX_TIM7_Init(void)
{

  TIM_MasterConfigTypeDef sMasterConfig = {0};

  htim7.Instance = TIM7;
  htim7.Init.Prescaler = 119;
  htim7.Init.CounterMode = TIM_COUNTERMODE_UP;
  htim7.Init.Period = 1000;
  htim7.Init.AutoReloadPreload = TIM_AUTORELOAD_PRELOAD_ENABLE;
  if (HAL_TIM_Base_Init(&htim7) != HAL_OK)
  {
    Error_Handler();
  }
  sMasterConfig.MasterOutputTrigger = TIM_TRGO_RESET;
  sMasterConfig.MasterSlaveMode = TIM_MASTERSLAVEMODE_DISABLE;
  if (HAL_TIMEx_MasterConfigSynchronization(&htim7, &sMasterConfig) != HAL_OK)
  {
    Error_Handler();
  }

}

static void MX_USART1_UART_Init(void)
{

  huart1.Instance = USART1;
  huart1.Init.BaudRate = 115200;
  huart1.Init.WordLength = UART_WORDLENGTH_8B;
  huart1.Init.StopBits = UART_STOPBITS_1;
  huart1.Init.Parity = UART_PARITY_NONE;
  huart1.Init.Mode = UART_MODE_TX_RX;
  huart1.Init.HwFlowCtl = UART_HWCONTROL_NONE;
  huart1.Init.OverSampling = UART_OVERSAMPLING_16;
  huart1.Init.OneBitSampling = UART_ONE_BIT_SAMPLE_DISABLE;
  huart1.Init.ClockPrescaler = UART_PRESCALER_DIV1;
  huart1.AdvancedInit.AdvFeatureInit = UART_ADVFEATURE_NO_INIT;
  if (HAL_UART_Init(&huart1) != HAL_OK)
  {
    Error_Handler();
  }
  if (HAL_UARTEx_SetTxFifoThreshold(&huart1, UART_TXFIFO_THRESHOLD_1_8) != HAL_OK)
  {
    Error_Handler();
  }
  if (HAL_UARTEx_SetRxFifoThreshold(&huart1, UART_RXFIFO_THRESHOLD_1_8) != HAL_OK)
  {
    Error_Handler();
  }
  if (HAL_UARTEx_DisableFifoMode(&huart1) != HAL_OK)
  {
    Error_Handler();
  }

}

static void MX_USART2_UART_Init(void)
{

  huart2.Instance = USART2;
  huart2.Init.BaudRate = 115200;
  huart2.Init.WordLength = UART_WORDLENGTH_8B;
  huart2.Init.StopBits = UART_STOPBITS_1;
  huart2.Init.Parity = UART_PARITY_NONE;
  huart2.Init.Mode = UART_MODE_TX_RX;
  huart2.Init.HwFlowCtl = UART_HWCONTROL_NONE;
  huart2.Init.OverSampling = UART_OVERSAMPLING_16;
  huart2.Init.OneBitSampling = UART_ONE_BIT_SAMPLE_DISABLE;
  huart2.Init.ClockPrescaler = UART_PRESCALER_DIV1;
  huart2.AdvancedInit.AdvFeatureInit = UART_ADVFEATURE_NO_INIT;
  huart2.FifoMode = UART_FIFOMODE_DISABLE;
  if (HAL_RS485Ex_Init(&huart2, UART_DE_POLARITY_HIGH, 0, 0) != HAL_OK)
  {
    Error_Handler();
  }
  if (HAL_UARTEx_SetTxFifoThreshold(&huart2, UART_TXFIFO_THRESHOLD_1_8) != HAL_OK)
  {
    Error_Handler();
  }
  if (HAL_UARTEx_SetRxFifoThreshold(&huart2, UART_RXFIFO_THRESHOLD_1_8) != HAL_OK)
  {
    Error_Handler();
  }
  if (HAL_UARTEx_DisableFifoMode(&huart2) != HAL_OK)
  {
    Error_Handler();
  }

}

static void MX_DMA_Init(void)
{

  /* DMA controller clock enable */
  __HAL_RCC_DMAMUX1_CLK_ENABLE();
  __HAL_RCC_DMA1_CLK_ENABLE();

  /* DMA interrupt init */
  /* DMA1_Channel1_IRQn interrupt configuration */
  HAL_NVIC_SetPriority(DMA1_Channel1_IRQn, 5, 0);
  HAL_NVIC_EnableIRQ(DMA1_Channel1_IRQn);
  /* DMA1_Channel2_IRQn interrupt configuration */
  HAL_NVIC_SetPriority(DMA1_Channel2_IRQn, 5, 0);
  HAL_NVIC_EnableIRQ(DMA1_Channel2_IRQn);
  /* DMA1_Channel3_IRQn interrupt configuration */
  HAL_NVIC_SetPriority(DMA1_Channel3_IRQn, 5, 0);
  HAL_NVIC_EnableIRQ(DMA1_Channel3_IRQn);

}

static void MX_GPIO_Init(void)
{
  GPIO_InitTypeDef GPIO_InitStruct = {0};

  /* GPIO Ports Clock Enable */
  __HAL_RCC_GPIOE_CLK_ENABLE();
  __HAL_RCC_GPIOC_CLK_ENABLE();
  __HAL_RCC_GPIOH_CLK_ENABLE();
  __HAL_RCC_GPIOA_CLK_ENABLE();
  __HAL_RCC_GPIOB_CLK_ENABLE();
  __HAL_RCC_GPIOD_CLK_ENABLE();

  /*Configure GPIO pin Output Level */
  HAL_GPIO_WritePin(GPIOE, LCD_HEATER_Pin|ENABLE_USB_SUPPLY_Pin, GPIO_PIN_RESET);

  /*Configure GPIO pin Output Level */
  HAL_GPIO_WritePin(GPIOC, ENABLE_CURRENT_AIN2_Pin|DIGITAL_OUT1_Pin|DIGITAL_OUT2_Pin|DOUT_nRED_LED_Pin
                          |DOUT_nRUN_LED_Pin, GPIO_PIN_RESET);

  /*Configure GPIO pin Output Level */
  HAL_GPIO_WritePin(nCAN_RESISTOR_ENABLE_GPIO_Port, nCAN_RESISTOR_ENABLE_Pin, GPIO_PIN_SET);

  /*Configure GPIO pin Output Level */
  HAL_GPIO_WritePin(LTDC_RESET_GPIO_Port, LTDC_RESET_Pin, GPIO_PIN_SET);

  /*Configure GPIO pin Output Level */
  HAL_GPIO_WritePin(GPIOD, ENABLE_RESISTIVE_AIN2_Pin|ENABLE_RESISTIVE_AIN1_Pin, GPIO_PIN_RESET);

  /*Configure GPIO pin Output Level */
  HAL_GPIO_WritePin(ENABLE_CURRENT_AIN1_GPIO_Port, ENABLE_CURRENT_AIN1_Pin, GPIO_PIN_RESET);

  /*Configure GPIO pin : nBUTTON1_Pin */
  GPIO_InitStruct.Pin = nBUTTON1_Pin;
  GPIO_InitStruct.Mode = GPIO_MODE_INPUT;
  GPIO_InitStruct.Pull = GPIO_NOPULL;
  HAL_GPIO_Init(nBUTTON1_GPIO_Port, &GPIO_InitStruct);

  /*Configure GPIO pins : LCD_HEATER_Pin ENABLE_USB_SUPPLY_Pin */
  GPIO_InitStruct.Pin = LCD_HEATER_Pin|ENABLE_USB_SUPPLY_Pin;
  GPIO_InitStruct.Mode = GPIO_MODE_OUTPUT_PP;
  GPIO_InitStruct.Pull = GPIO_NOPULL;
  GPIO_InitStruct.Speed = GPIO_SPEED_FREQ_LOW;
  HAL_GPIO_Init(GPIOE, &GPIO_InitStruct);

  /*Configure GPIO pins : ENABLE_CURRENT_AIN2_Pin LTDC_RESET_Pin DIGITAL_OUT1_Pin DIGITAL_OUT2_Pin
                           DOUT_nRED_LED_Pin DOUT_nRUN_LED_Pin */
  GPIO_InitStruct.Pin = ENABLE_CURRENT_AIN2_Pin|LTDC_RESET_Pin|DIGITAL_OUT1_Pin|DIGITAL_OUT2_Pin
                          |DOUT_nRED_LED_Pin|DOUT_nRUN_LED_Pin;
  GPIO_InitStruct.Mode = GPIO_MODE_OUTPUT_PP;
  GPIO_InitStruct.Pull = GPIO_NOPULL;
  GPIO_InitStruct.Speed = GPIO_SPEED_FREQ_LOW;
  HAL_GPIO_Init(GPIOC, &GPIO_InitStruct);

  /*Configure GPIO pin : uC_FREQ_IN_Pin */
  GPIO_InitStruct.Pin = uC_FREQ_IN_Pin;
  GPIO_InitStruct.Mode = GPIO_MODE_IT_FALLING;
  GPIO_InitStruct.Pull = GPIO_NOPULL;
  HAL_GPIO_Init(uC_FREQ_IN_GPIO_Port, &GPIO_InitStruct);

  /*Configure GPIO pin : nCAN_RESISTOR_ENABLE_Pin */
  GPIO_InitStruct.Pin = nCAN_RESISTOR_ENABLE_Pin;
  GPIO_InitStruct.Mode = GPIO_MODE_OUTPUT_PP;
  GPIO_InitStruct.Pull = GPIO_NOPULL;
  GPIO_InitStruct.Speed = GPIO_SPEED_FREQ_LOW;
  HAL_GPIO_Init(nCAN_RESISTOR_ENABLE_GPIO_Port, &GPIO_InitStruct);

  /*Configure GPIO pins : nBUTTON2_Pin nBUTTON3_Pin */
  GPIO_InitStruct.Pin = nBUTTON2_Pin|nBUTTON3_Pin;
  GPIO_InitStruct.Mode = GPIO_MODE_INPUT;
  GPIO_InitStruct.Pull = GPIO_NOPULL;
  HAL_GPIO_Init(GPIOB, &GPIO_InitStruct);

  /*Configure GPIO pins : nBUTTON0_Pin FW_UPDATE_ENABLE_Pin */
  GPIO_InitStruct.Pin = nBUTTON0_Pin|FW_UPDATE_ENABLE_Pin;
  GPIO_InitStruct.Mode = GPIO_MODE_INPUT;
  GPIO_InitStruct.Pull = GPIO_NOPULL;
  HAL_GPIO_Init(GPIOC, &GPIO_InitStruct);

  /*Configure GPIO pins : ENABLE_RESISTIVE_AIN2_Pin ENABLE_RESISTIVE_AIN1_Pin */
  GPIO_InitStruct.Pin = ENABLE_RESISTIVE_AIN2_Pin|ENABLE_RESISTIVE_AIN1_Pin;
  GPIO_InitStruct.Mode = GPIO_MODE_OUTPUT_PP;
  GPIO_InitStruct.Pull = GPIO_NOPULL;
  GPIO_InitStruct.Speed = GPIO_SPEED_FREQ_LOW;
  HAL_GPIO_Init(GPIOD, &GPIO_InitStruct);

  /*Configure GPIO pin : ENABLE_CURRENT_AIN1_Pin */
  GPIO_InitStruct.Pin = ENABLE_CURRENT_AIN1_Pin;
  GPIO_InitStruct.Mode = GPIO_MODE_OUTPUT_PP;
  GPIO_InitStruct.Pull = GPIO_NOPULL;
  GPIO_InitStruct.Speed = GPIO_SPEED_FREQ_LOW;
  HAL_GPIO_Init(ENABLE_CURRENT_AIN1_GPIO_Port, &GPIO_InitStruct);

  /* EXTI interrupt init*/
  HAL_NVIC_SetPriority(EXTI2_IRQn, 5, 0);
  HAL_NVIC_EnableIRQ(EXTI2_IRQn);

}

/* USER CODE BEGIN 4 */

// used by printf
int __io_putchar(int ch)
{
#ifdef USE_PRINTF
    HAL_UART_Transmit(phuart, (uint8_t *)&ch, 1, HAL_UART_TIMEOUT_VALUE);
#endif

    return ch;
}

// Frequency input GPIO ISR
__weak void FreqInCallback(void)
{
	if(++freq_sample_count > 9){
		freq_timer = TIM6->CNT + timer6_byte3;
		freq_sample_count = 0;
		TIM6->CNT = 0;
		timer6_byte3 = 0;
		frequency_valid = true;
	}
}

/* USER CODE END 4 */

void StartDefaultTask(void *argument)
{
  /* init code for USB_DEVICE */
  MX_USB_DEVICE_Init();
  /* USER CODE BEGIN 5 */
  //Switch LEDs off
   	HAL_GPIO_WritePin(DOUT_nRED_LED_GPIO_Port, DOUT_nRED_LED_Pin, 1);
   	HAL_GPIO_WritePin(DOUT_nRUN_LED_GPIO_Port, DOUT_nRUN_LED_Pin, 1);

   	//Initialise 1mS 'Tick' timers
   	initialise_timers();

   	//Setup littleFS
   	FS_Init(); // Init littlefs file system

   	//Load S35 configuration data
   	LoadConfigFile();

   	//Update all features affected by config change or on power up
   	UpdateAllConfigFeatures();

   	/* Infinite loop */
   	for(;;)
   	{
   		//Update all 10mS tick timers
   		update_tick_timers();

   		//CAN communications
   		CAN_transmit_coms();
   		CAN_receive_coms();

   		//PDM communications
   		PDM_comms();

   		//Engine App
   		engine_app();

   		//I/O MAPPING
   		IO_Mapping_Update();

   		//Digital output control
   		digital_output_control();

   		//Frequency measurement
   		process_frequency_measurement();

   		//Analogue input setup
		setup_input_hardware();

		//Process analogue inputs
		//process_analogue_inputs();

  		//LCD heater control
  		lcd_heater_control();

   		osDelay(1);
   	}

  /* USER CODE END 5 */
}

void StartTouchGfx(void *argument)
{
  /* USER CODE BEGIN StartTouchGfx */
  HAL_TIM_PWM_Start(&htim2, TIM_CHANNEL_2); // enable backlight PWM output
  TIM2->CCR2 = 200;

  MX_TouchGFX_Process();
  /* Infinite loop */
  for(;;)
  {
    osDelay(1);
  }
  /* USER CODE END StartTouchGfx */
}

void HAL_TIM_PeriodElapsedCallback(TIM_HandleTypeDef *htim)
{
  if (htim->Instance == TIM1)
  {
    HAL_IncTick();
  }
  /* USER CODE BEGIN Callback 1 */
  else if (htim->Instance == TIM6)
   {
    	  //Frequency measurement timer
    	  timer6_byte3 += 0x00010000;

    	  if(timer6_byte3 > 0x00200000)
    	  {
    		  //Overflow: Frequency too low to measure
    		  frequency_valid = false;
    		  timer6_byte3 = 0x00200000;
    	  }
   }

  /* USER CODE END Callback 1 */
}

void Error_Handler(void)
{
  __disable_irq();
  while (1)
  {
  }
}
